# ATSAM3U1E register map
Vendor: Atmel; File version: 0
CPU: CM3 r2p0, selectable endian, no MPU, no FPU, 0x4 interrupt priority bits, 0x0 interrupts
Registers are 32-bit, read-write, no defined reset value unless marked. A register's access mark holds for its fields unless they carry their own. Offsets are from the block's base; [hi:lo] are bit positions; {n}, {i} and the like mark numbered series.

## PIOA — Parallel Input/Output Controller A
Base 0x400E0C00; register names take the prefix PIOA_
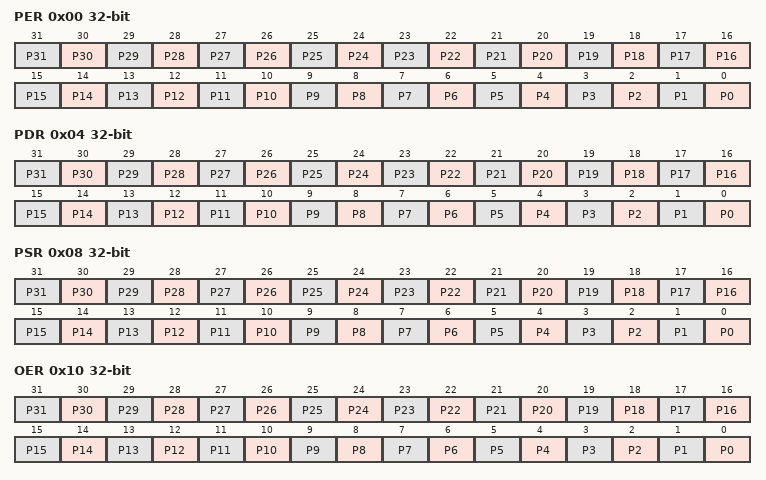
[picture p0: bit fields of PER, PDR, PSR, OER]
0x00 PER wo — PIO Enable Register
  [n] P{n} (n=0..31) — PIO Enable
0x04 PDR wo — PIO Disable Register
  [n] P{n} (n=0..31) — PIO Disable
0x08 PSR ro — PIO Status Register
  [n] P{n} (n=0..31) — PIO Status
0x10 OER wo — Output Enable Register
  [n] P{n} (n=0..31) — Output Enable
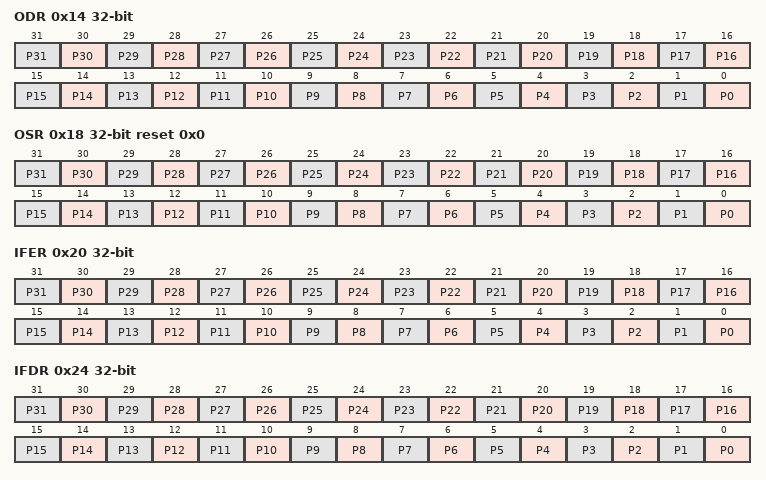
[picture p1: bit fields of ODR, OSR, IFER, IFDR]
0x14 ODR wo — Output Disable Register
  [n] P{n} (n=0..31) — Output Disable
0x18 OSR ro reset 0x0 — Output Status Register
  [n] P{n} (n=0..31) — Output Status
0x20 IFER wo — Glitch Input Filter Enable Register
  [n] P{n} (n=0..31) — Input Filter Enable
0x24 IFDR wo — Glitch Input Filter Disable Register
  [n] P{n} (n=0..31) — Input Filter Disable
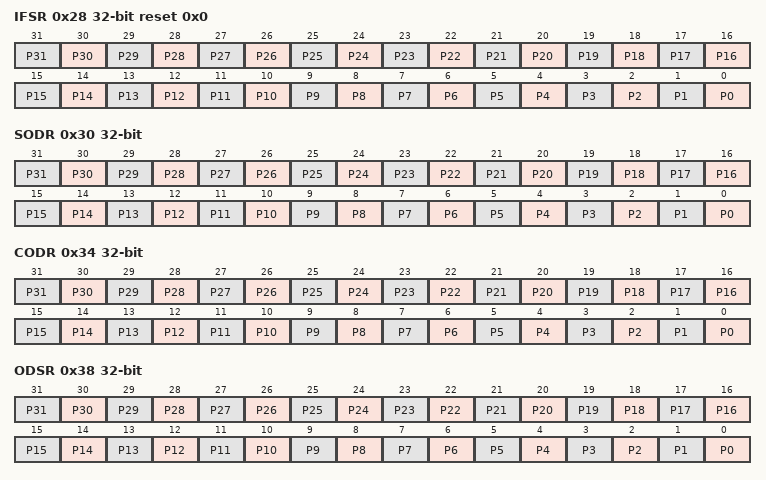
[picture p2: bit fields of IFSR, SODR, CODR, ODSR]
0x28 IFSR ro reset 0x0 — Glitch Input Filter Status Register
  [n] P{n} (n=0..31) — Input Filer Status
0x30 SODR wo — Set Output Data Register
  [n] P{n} (n=0..31) — Set Output Data
0x34 CODR wo — Clear Output Data Register
  [n] P{n} (n=0..31) — Clear Output Data
0x38 ODSR — Output Data Status Register
  [n] P{n} (n=0..31) — Output Data Status
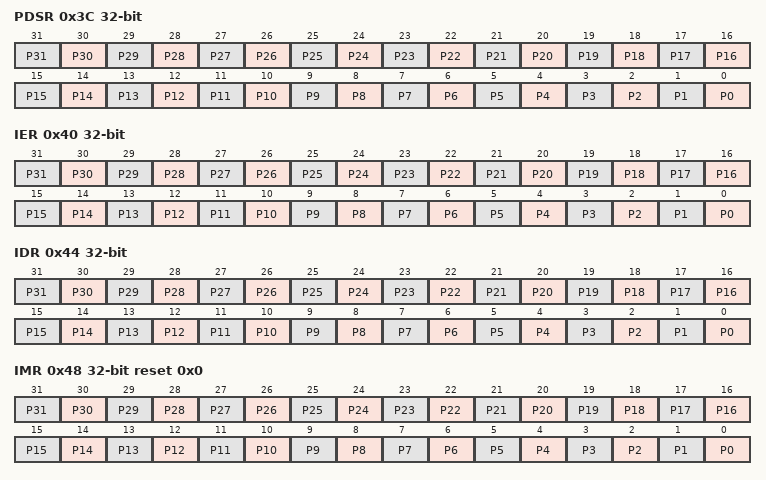
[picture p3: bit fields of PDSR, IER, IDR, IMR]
0x3C PDSR ro — Pin Data Status Register
  [n] P{n} (n=0..31) — Output Data Status
0x40 IER wo — Interrupt Enable Register
  [n] P{n} (n=0..31) — Input Change Interrupt Enable
0x44 IDR wo — Interrupt Disable Register
  [n] P{n} (n=0..31) — Input Change Interrupt Disable
0x48 IMR ro reset 0x0 — Interrupt Mask Register
  [n] P{n} (n=0..31) — Input Change Interrupt Mask
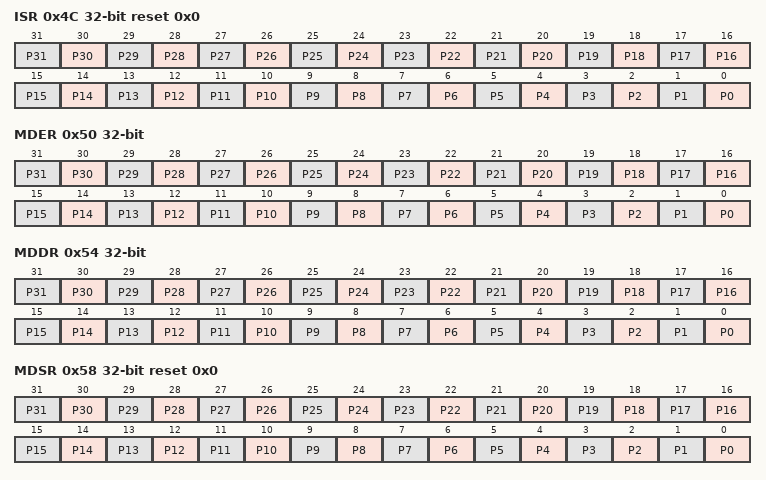
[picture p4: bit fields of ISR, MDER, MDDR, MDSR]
0x4C ISR ro reset 0x0 — Interrupt Status Register
  [n] P{n} (n=0..31) — Input Change Interrupt Status
0x50 MDER wo — Multi-driver Enable Register
  [n] P{n} (n=0..31) — Multi Drive Enable.
0x54 MDDR wo — Multi-driver Disable Register
  [n] P{n} (n=0..31) — Multi Drive Disable.
0x58 MDSR ro reset 0x0 — Multi-driver Status Register
  [n] P{n} (n=0..31) — Multi Drive Status.
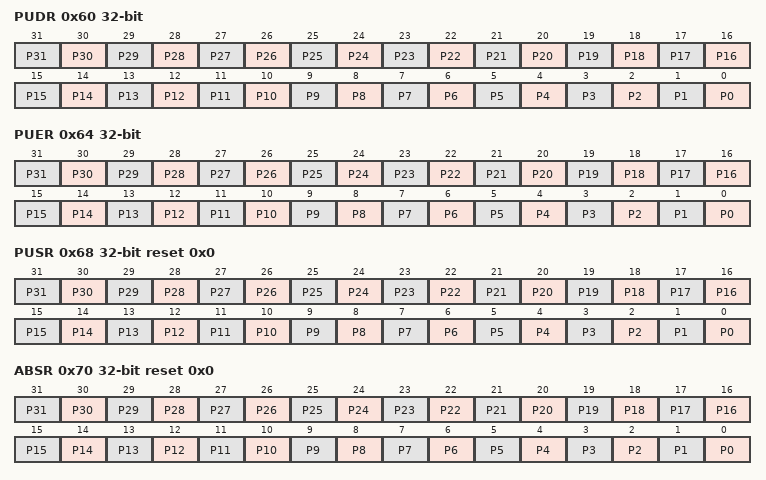
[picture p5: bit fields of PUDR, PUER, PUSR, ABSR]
0x60 PUDR wo — Pull-up Disable Register
  [n] P{n} (n=0..31) — Pull Up Disable.
0x64 PUER wo — Pull-up Enable Register
  [n] P{n} (n=0..31) — Pull Up Enable.
0x68 PUSR ro reset 0x0 — Pad Pull-up Status Register
  [n] P{n} (n=0..31) — Pull Up Status.
0x70 ABSR reset 0x0 — Peripheral AB Select Register
  [n] P{n} (n=0..31) — Peripheral A Select.
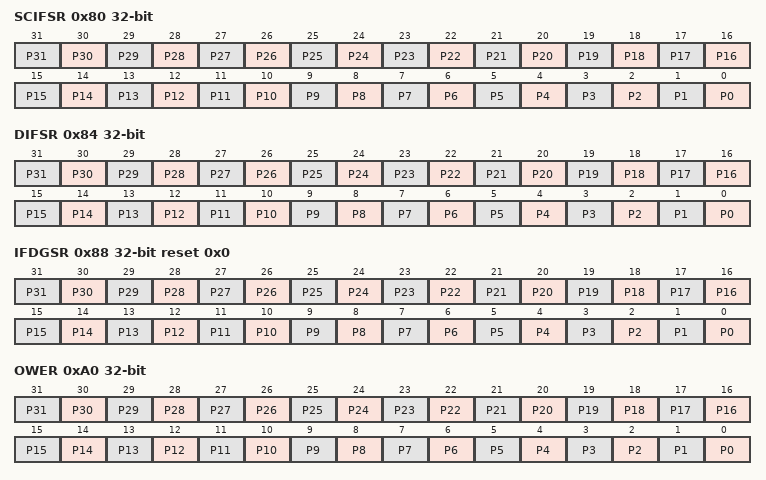
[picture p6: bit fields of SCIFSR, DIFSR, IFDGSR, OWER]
0x80 SCIFSR wo — System Clock Glitch Input Filter Select Register
  [n] P{n} (n=0..31) — System Clock Glitch Filtering Select.
0x84 DIFSR wo — Debouncing Input Filter Select Register
  [n] P{n} (n=0..31) — Debouncing Filtering Select.
0x88 IFDGSR ro reset 0x0 — Glitch or Debouncing Input Filter Clock Selection Status Register
  [n] P{n} (n=0..31) — Glitch or Debouncing Filter Selection Status
0x8C SCDR reset 0x0 — Slow Clock Divider Debouncing Register
  [13:0] DIV — Slow Clock Divider Selection for Debouncing
0xA0 OWER wo — Output Write Enable
  [n] P{n} (n=0..31) — Output Write Enable.
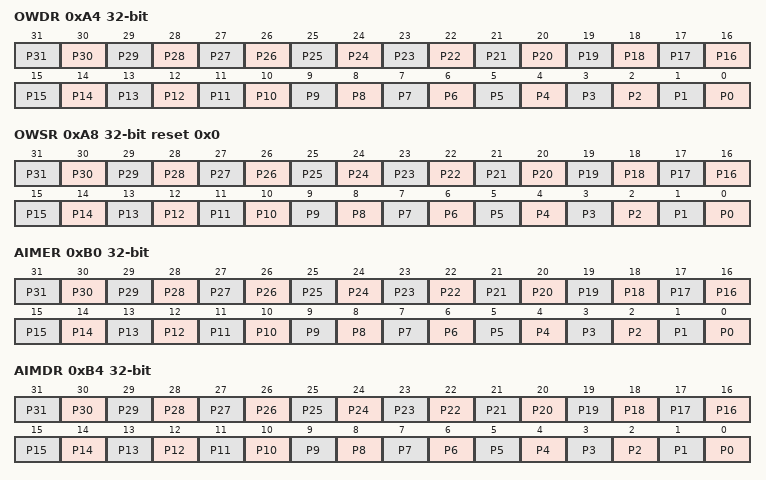
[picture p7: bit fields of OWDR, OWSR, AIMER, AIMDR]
0xA4 OWDR wo — Output Write Disable
  [n] P{n} (n=0..31) — Output Write Disable.
0xA8 OWSR ro reset 0x0 — Output Write Status Register
  [n] P{n} (n=0..31) — Output Write Status.
0xB0 AIMER wo — Additional Interrupt Modes Enable Register
  [n] P{n} (n=0..31) — Additional Interrupt Modes Enable.
0xB4 AIMDR wo — Additional Interrupt Modes Disables Register
  [n] P{n} (n=0..31) — Additional Interrupt Modes Disable.
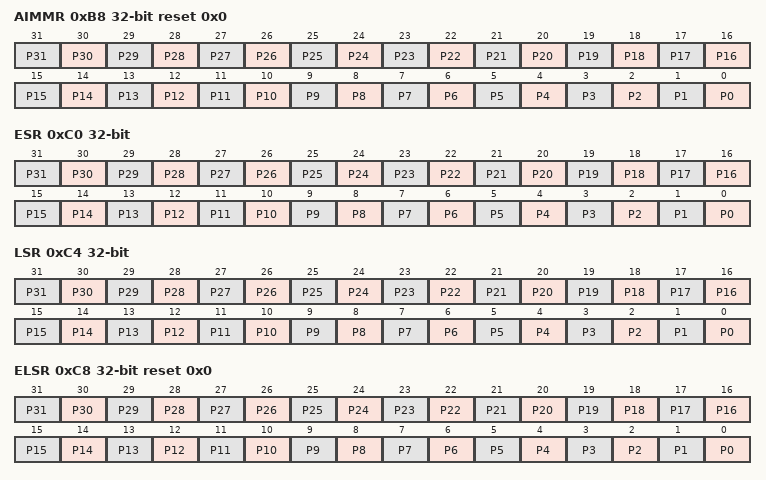
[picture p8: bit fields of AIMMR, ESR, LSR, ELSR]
0xB8 AIMMR ro reset 0x0 — Additional Interrupt Modes Mask Register
  [n] P{n} (n=0..31) — Peripheral CD Status.
0xC0 ESR wo — Edge Select Register
  [n] P{n} (n=0..31) — Edge Interrupt Selection.
0xC4 LSR wo — Level Select Register
  [n] P{n} (n=0..31) — Level Interrupt Selection.
0xC8 ELSR ro reset 0x0 — Edge/Level Status Register
  [n] P{n} (n=0..31) — Edge/Level Interrupt source selection.
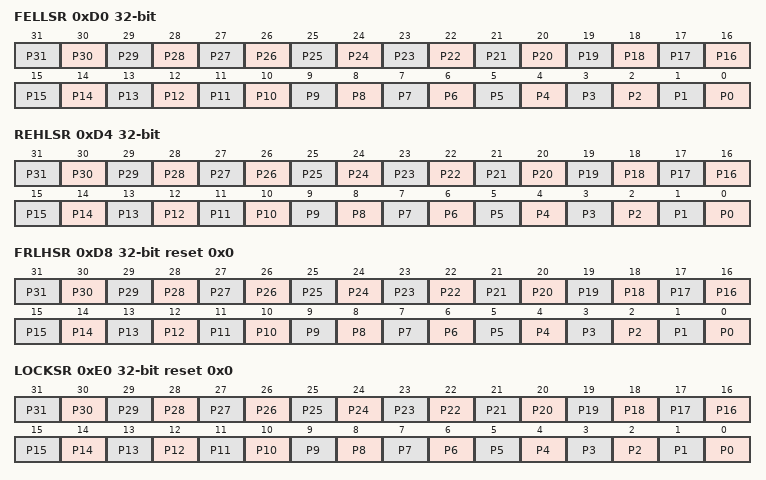
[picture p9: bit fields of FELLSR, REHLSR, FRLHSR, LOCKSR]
0xD0 FELLSR wo — Falling Edge/Low Level Select Register
  [n] P{n} (n=0..31) — Falling Edge/Low Level Interrupt Selection.
0xD4 REHLSR wo — Rising Edge/ High Level Select Register
  [n] P{n} (n=0..31) — Rising Edge /High Level Interrupt Selection.
0xD8 FRLHSR ro reset 0x0 — Fall/Rise - Low/High Status Register
  [n] P{n} (n=0..31) — Edge /Level Interrupt Source Selection.
0xE0 LOCKSR ro reset 0x0 — Lock Status
  [n] P{n} (n=0..31) — Lock Status.
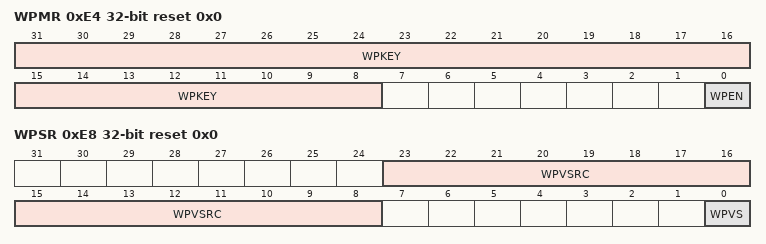
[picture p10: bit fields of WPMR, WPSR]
0xE4 WPMR reset 0x0 — Write Protect Mode Register
  [31:8] WPKEY — Write Protect KEY
  [0] WPEN — Write Protect Enable
0xE8 WPSR ro reset 0x0 — Write Protect Status Register
  [23:8] WPVSRC — Write Protect Violation Source
  [0] WPVS — Write Protect Violation Status

## PIOB — Parallel Input/Output Controller B
Base 0x400E0E00; register names take the prefix PIOB_
Registers as PIOA.

## PIOC — Parallel Input/Output Controller C
Base 0x400E1000; register names take the prefix PIOC_
Registers as PIOA.
